# A33M11x register map
Vendor: ABOV Semiconductor Co., Ltd.; File version: 1.0
CPU: CM3 r0p1, little endian, MPU, FPU, VTOR, 4 interrupt priority bits
Registers are 32-bit, read-write, reset 0x0 unless marked. A register's access mark holds for its fields unless they carry their own. Offsets are from the block's base; [hi:lo] are bit positions; {n}, {i} and the like mark numbered series; 'fields as' and 'values as' point back to an identical list.

## MPWM0 — Motor Pulse Width Modulation
Base 0x40004000
Same registers: MPWM1 0x40005000
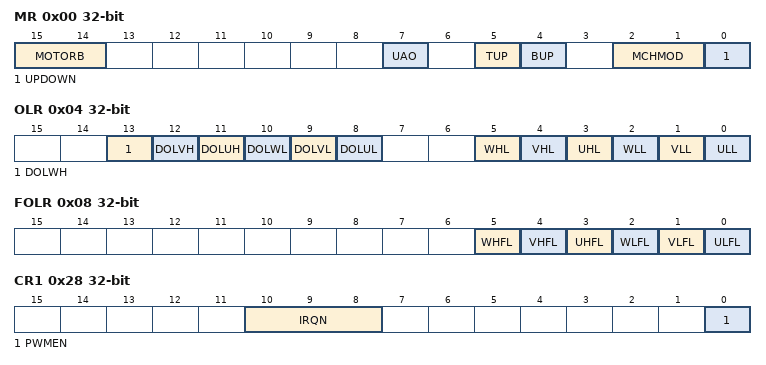
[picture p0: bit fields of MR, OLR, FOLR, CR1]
0x00 MR — MPWM n Mode Register
  [15:14] MOTORB — MPWM Mode Selection Bit
    0=MOTOR_PWM (Motor PWM Mode); 1=NORMAL_PWM (Normal PWM Mode); 3=EXTEND_PWM (Extend PWM Mode)
  [7] UAO — Update Timing Selection Bit
    0=DESIGNATE (Designate timing update); 1=ONCE (Once Duty Period Update)
  [5] TUP — DUTY, Period Update Enable bit (When same period)
    0=None Update; 1=Update
  [4] BUP — DUTY, Period Update Enable bit (When same bottom)
    0=None Update; 1=Update
  [2:1] MCHMOD — Channel Symmetry/Asymmetry Mode Selection Bit
    0=2-ch symmetry mode; 1=1-ch asymmetry mode; 2=1-ch symmetry mode
  [0] UPDOWN — PWM Up/Down Counter Mode Selection Bit
    0=UP (PWM Up Counter Mode(MOTORB = 1)); 1=UP_DOWN (Up/Down Counter Mode (MOTORB = 0, 1, 3))
0x04 OLR — MPWM n Output Level Register
  [13] DOLWH — Output level selection bit when PWMxH Disable
    0=LOW (Low Level); 1=HIGH (High Level)
  [12] DOLVH — Output level selection bit when PWMxH Disable
    0=LOW (Low Level); 1=HIGH (High Level)
  [11] DOLUH — Output level selection bit when PWMxH Disable
    0=LOW (Low Level); 1=HIGH (High Level)
  [10] DOLWL — Output level selection bit when PWMxL Disable
    0=LOW (Low Level); 1=HIGH (High Level)
  [9] DOLVL — Output level selection bit when PWMxL Disable
    0=LOW (Low Level); 1=HIGH (High Level)
  [8] DOLUL — Output level selection bit when PWMxL Disable
    0=LOW (Low Level); 1=HIGH (High Level)
  [5] WHL — Output polarity selection bit when PWMxH Start
    0=LOW (default output level(low level)); 1=HIGH (polarity output level(high level))
  [4] VHL — Output polarity selection bit when PWMxH Start
    values as WHL
  [3] UHL — Output polarity selection bit when PWMxH Start
    values as WHL
  [2] WLL — Output polarity selection bit when PWMxL Start
    values as WHL
  [1] VLL — Output polarity selection bit when PWMxL Start
    values as WHL
  [0] ULL — Output polarity selection bit when PWMxL Start
    values as WHL
0x08 FOLR — MPWM n compulsion Output Register
  [all] fields
    0=LOW (compulsion output level low); 1=HIGH (compulsion output level high)
  [5] WHFL — WH Compulsion output level selection bit
  [4] VHFL — VH Compulsion output level selection bit
  [3] UHFL — UH Compulsion output level selection bit
  [2] WLFL — WL Compulsion output level selection bit
  [1] VLFL — VL Compulsion output level selection bit
  [0] ULFL — UL Compulsion output level selection bit
0x0C PRD reset 0x2 — MPWM n Period Register
  [15:0] PERIOD — 16bit pwm period
0x10 DUH reset 0x1 — MPWM n DUTY x Register
  [15:0] DUTY_UH — 16 bit PWM Duty setting bit for X output
0x14 DVH reset 0x1 — MPWM n DUTY x Register
  [15:0] DUTY_VH — 16 bit PWM Duty setting bit for X output
0x18 DWH reset 0x1 — MPWM n DUTY x Register
  [15:0] DUTY_WH — 16 bit PWM Duty setting bit for X output
0x1C DUL reset 0x1 — MPWM n DUTY x Register
  [15:0] DUTY_UL — 16 bit PWM Duty setting bit for X output
0x20 DVL reset 0x1 — MPWM n DUTY x Register
  [15:0] DUTY_VL — 16 bit PWM Duty setting bit for X output
0x24 DWL reset 0x1 — MPWM n DUTY x Register
  [15:0] DUTY_WL — 16 bit PWM Duty setting bit for X output
0x28 CR1 — MPWM n Control Register 1
  [10:8] IRQN — IRQ number
  [0] PWMEN — PWM Enable Bit
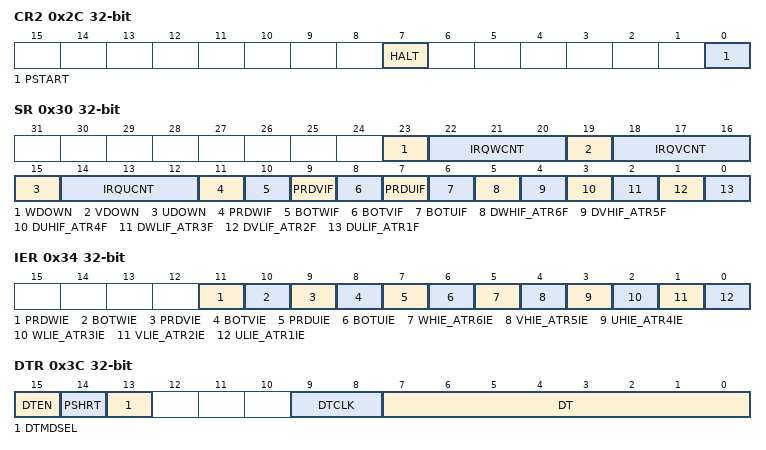
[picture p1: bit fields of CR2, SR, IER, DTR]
0x2C CR2 — MPWM n Control Register 2
  [7] HALT — PWM HALT
  [0] PSTART — PWM Phase x counter start
0x30 SR — MPWM n Status Register
  [23] WDOWN ro — Current PWM Counter Mode
  [22:20] IRQWCNT ro — Interrupt Counter Number of Period Match
  [19] VDOWN ro — Current PWM Counter Mode
  [18:16] IRQVCNT ro — Interrupt Counter Number of Period Match
  [15] UDOWN ro — Current PWM Counter Mode
  [14:12] IRQUCNT ro — Interrupt Counter Number of Period Match
  [11] PRDWIF — PWM Period Interrupt Flag
  [10] BOTWIF — PWM Bottom Interrupt Flag
  [9] PRDVIF — PWM Period Interrupt Flag
  [8] BOTVIF — PWM Bottom Interrupt Flag
  [7] PRDUIF — PWM Period Interrupt Flag
  [6] BOTUIF — PWM Bottom Interrupt Flag
  [5] DWHIF_ATR6F — PWM Duty Interrupt Flag (Duty Interrupt Enable when ATR6 disable)
  [4] DVHIF_ATR5F — PWM Duty Interrupt Flag (Duty Interrupt Enable when ATR6 disable)
  [3] DUHIF_ATR4F — PWM Duty Interrupt Flag (Duty Interrupt Enable when ATR6 disable)
  [2] DWLIF_ATR3F — PWM Duty Interrupt Flag (Duty Interrupt Enable when ATR6 disable)
  [1] DVLIF_ATR2F — PWM Duty Interrupt Flag (Duty Interrupt Enable when ATR6 disable)
  [0] DULIF_ATR1F — PWM Duty Interrupt Flag (Duty Interrupt Enable when ATR6 disable)
0x34 IER — MPWM n Interrupt Enable Register
  [11] PRDWIE — PWM Counter Period Interrupt Enable bit
  [10] BOTWIE — PWM Counter Botom Interrupt Enable bit
  [9] PRDVIE — PWM Counter Period Interrupt Enable bit
  [8] BOTVIE — PWM Counter Botom Interrupt Enable bit
  [7] PRDUIE — PWM Counter Period Interrupt Enable bit
  [6] BOTUIE — PWM Counter Botom Interrupt Enable bit
  [5] WHIE_ATR6IE — Duty or ATR6 Match Interrupt Enable bit
  [4] VHIE_ATR5IE — Duty or ATR5 Match Interrupt Enable bit
  [3] UHIE_ATR4IE — Duty or ATR4 Match Interrupt Enable bit
  [2] WLIE_ATR3IE — Duty or ATR3 Match Interrupt Enable bit
  [1] VLIE_ATR2IE — Duty or ATR2 Match Interrupt Enable bit
  [0] ULIE_ATR1IE — Duty or ATR1 Match Interrupt Enable bit
0x38 CNT — MPWM n Counter Register
  [15:0] CNT — PWM Counter Value
0x3C DTR — MPWM n Dead-Time Register
  [15] DTEN — Dead-time Function Enable Bit
  [14] PSHRT — Short Protecion Bit
  [13] DTMDSEL — Dead-time Operation Mode Selection Bit
    0=Before_H_After_L (Insert Before of PWMxH, After of PWMxL); 1=Before_L_After_H (Insert Before of PWMxL, After of PWMxH)
  [9:8] DTCLK — Dead-time Prescaler Setting Bit
    0=PWMCLK_BY_2 (Dead-time counter is PWM CLK/2); 1=PWMCLK_BY_4 (Dead-time counter is PWM CLK/4); 2=PWMCLK_BY_8 (Dead-time counter is PWM CLK/8); 3=PWMCLK_BY_16 (Dead-time counter is PWM CLK/16)
  [7:0] DT — Rising/Falling Edge Dead-time Value
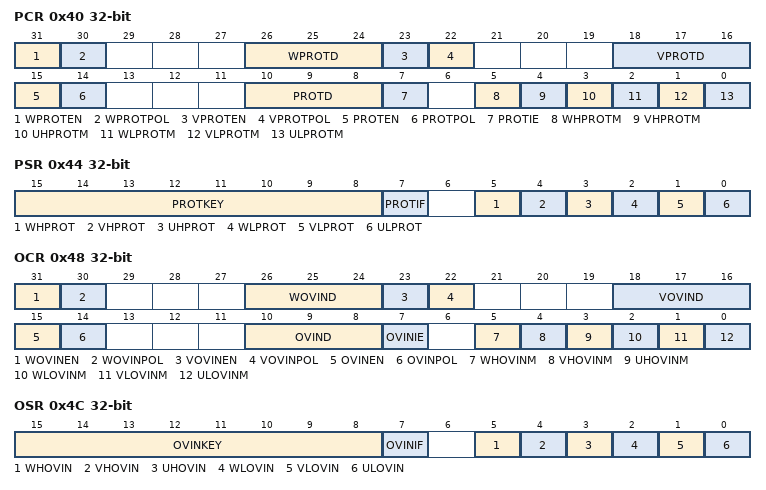
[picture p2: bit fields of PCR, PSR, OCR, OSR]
0x40 PCR — MPWM n Protection Control Register
  [31] WPROTEN — Protection Input Enable
  [30] WPROTPOL — Protection Input Polarity Selection Bit
  [26:24] WPROTD — Protection Input Debounce
  [23] VPROTEN — Protection Input Enable
  [22] VPROTPOL — Protection Input Polarity Selection Bit
  [18:16] VPROTD — Protection Input Debounce
  [15] PROTEN — Protection Input Enable
  [14] PROTPOL — Protection Input Polarity Selection
  [10:8] PROTD — Protection Input Debounce
  [7] PROTIE — Protection Interrupt Enable
  [5] WHPROTM — Ph-W, H Protection Output Enable
  [4] VHPROTM — Ph-V, H Protection Output Enable
  [3] UHPROTM — Ph-U, H Protection Output Enable
  [2] WLPROTM — Ph-W, L Protection Output Enable
  [1] VLPROTM — Ph-V, L Protection Output Enable
  [0] ULPROTM — Ph-U, L Protection Output Enable
0x44 PSR — MPWM n Protection Status Register
  [15:8] PROTKEY wo — Protection Clear Access Key (KEY : 0xCA)
  [7] PROTIF — Protection Interrupt Status
  [5] WHPROT — Ph-W, H Protection Flag
  [4] VHPROT — Ph-V, H Protection Flag
  [3] UHPROT — Ph-U, H Protection Flag
  [2] WLPROT — Ph-W, L Protection Flag
  [1] VLPROT — Ph-V, L Protection Flag
  [0] ULPROT — Ph-U, L Protection Flag
0x48 OCR — MPWM n Overvoltage Control Register
  [31] WOVINEN — Overvoltage Input Enable
  [30] WOVINPOL — Overvoltage Input Polarity Selection Bit
  [26:24] WOVIND — Overvoltage Input Debounce
  [23] VOVINEN — Overvoltage Input Enable
  [22] VOVINPOL — Overvoltage Input Polarity Selection Bit
  [18:16] VOVIND — Overvoltage Input Debounce
  [15] OVINEN — Overvoltage Input Enable
  [14] OVINPOL — Overvoltage Input Polarity Selection
  [10:8] OVIND — Overvoltage Input Debounce
  [7] OVINIE — Overvoltage Interrupt Enable
  [5] WHOVINM — Ph-W, H Protection Output Enable
  [4] VHOVINM — Ph-V, H Protection Output Enable
  [3] UHOVINM — Ph-U, H Protection Output Enable
  [2] WLOVINM — Ph-W, L Protection Output Enable
  [1] VLOVINM — Ph-V, L Protection Output Enable
  [0] ULOVINM — Ph-U, L Protection Output Enable
0x4C OSR — MPWM n Overvoltage Status Register
  [15:8] OVINKEY wo — Overvoltage Clear Access Key (KEY : 0xAC)
  [7] OVINIF — Overvoltage Interrupt Status
  [5] WHOVIN — Ph-W, H Protection Flag
  [4] VHOVIN — Ph-V, H Protection Flag
  [3] UHOVIN — Ph-U, H Protection Flag
  [2] WLOVIN — Ph-W, L Protection Flag
  [1] VLOVIN — Ph-V, L Protection Flag
  [0] ULOVIN — Ph-U, L Protection Flag
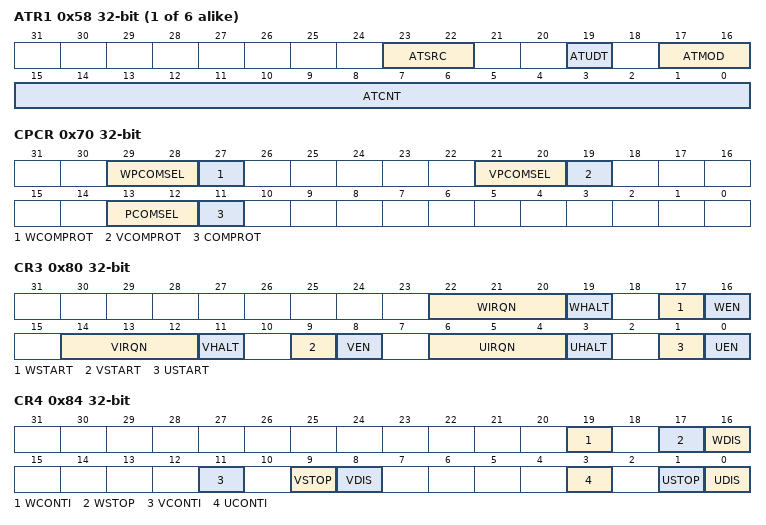
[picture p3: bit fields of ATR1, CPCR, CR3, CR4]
{0x54+4i} ATR{i} (i=1..6) — MPWM n ADC Trigger Counter m Register
  [23:22] ATSRC — ADC Trigger Source Counter
    0=Ph-U Counter Compare source; 1=Ph-V Counter Compare source; 2=Ph-W Counter Compare source
  [19] ATUDT — ADC Register Update Mode
  [17:16] ATMOD — ADC Trigger Mode Selection Register
    0=Disable (ADC Trigger Disable); 1=UP_Count (Trigger out When up counter match); 2=DOWN_Count (Trigger out When down counter match); 3=UP-DOWN_Count (Trigger out When up-down counter match)
  [15:0] ATCNT — ADC Trigger Counter (only less then PWM Period)
0x70 CPCR — MPWM n Comparator protection control Register
  [29:28] WPCOMSEL — Protection comparator peripheral selection (Phase W)
  [27] WCOMPROT — Whether to enable or disable comparator protection input (Phase W)
  [21:20] VPCOMSEL — Protection comparator peripheral selection (Phase V)
  [19] VCOMPROT — Whether to enable or disable comparator protection input (Phase V)
  [13:12] PCOMSEL — Protection comparator peripheral selection (Phase U)
  [11] COMPROT — Whether to enable or disable comparator protection input (Phase U)
0x80 CR3 — MPWM n Control Register 3
  [22:20] WIRQN — Ph-W Interrupt Interval Setting
  [19] WHALT — Ph-W counter stop in current status
  [17] WSTART — Ph-W Start Bit
  [16] WEN — Ph-W Enable Bit
  [14:12] VIRQN — Ph-V Interrupt Interval Setting
  [11] VHALT — Ph-V counter stop in current status
  [9] VSTART — Ph-V Start Bit
  [8] VEN — Ph-V Enable Bit
  [6:4] UIRQN — Ph-U Interrupt Interval Setting
  [3] UHALT — Ph-U counter stop in current status
  [1] USTART — Ph-U Start Bit
  [0] UEN — Ph-V Enable Bit
0x84 CR4 — MPWM n Control Register 4
  [19] WCONTI — Ph-W Counter Continuous Setting
  [17] WSTOP — Ph-W Counter Stop and Reset Setting
  [16] WDIS — Ph-W Disable Setting (Status reset)
  [11] VCONTI — Ph-V Counter Continuous Setting
  [9] VSTOP — Ph-V Counter Stop and Reset Setting
  [8] VDIS — Ph-W Disable Setting (Status reset)
  [3] UCONTI — Ph-U Counter Continuous Setting
  [1] USTOP — Ph-U Counter Stop and Reset Setting
  [0] UDIS — Ph-U Disable Setting (Status reset)
0x90 PRDU reset 0x2 — MPWM n Phase U Period Register
  [15:0] PERIOD_U — 16bit pwm period
0x94 PRDV reset 0x2 — MPWM n Phase V Period Register
  [15:0] PERIOD_V — 16bit pwm period
0x98 PRDW reset 0x2 — MPWM n Phase W Period Register
  [15:0] PERIOD_W — 16bit pwm period
0xA0 CNTU — MPWM n Counter U Register
  [15:0] CNT_U — PWM Counter Value
0xA4 CNTV — MPWM n Counter V Register
  [15:0] CNT_V — PWM Counter Value
0xA8 CNTW — MPWM n Counter W Register
  [15:0] CNT_W — PWM Counter Value
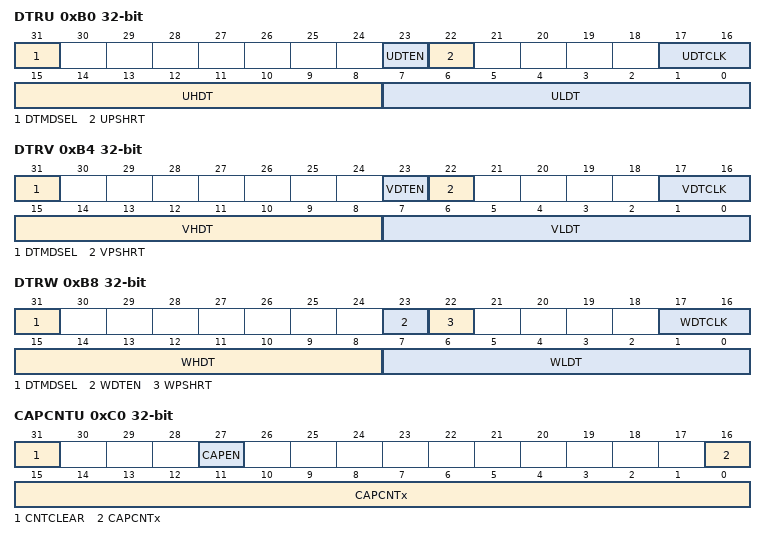
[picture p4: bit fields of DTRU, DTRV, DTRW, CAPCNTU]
0xB0 DTRU — MPWM n Dead-Time Register
  [31] DTMDSEL — Dead-time Operation Mode Selection Bit
    0=Before_H_After_L (dead-time insert before PWMxH, After PWMxL); 1=Before_L_After_H (dead-time insert before PWMxL, After PWMxH)
  [23] UDTEN — Dead-time Function Enable Bit
  [22] UPSHRT — Short Condition Protection
  [17:16] UDTCLK — Dead-time Prescaler
    values as DTR.DTCLK
  [15:8] UHDT — Rising Dead-time Value Bit
  [7:0] ULDT — Falling Dead-time Value Bit
0xB4 DTRV — MPWM n Dead-Time Register
  [31] DTMDSEL — Dead-time Operation Mode Selection Bit
    values as DTRU.DTMDSEL
  [23] VDTEN — Dead-time Function Enable Bit
  [22] VPSHRT — Short Condition Protection
  [17:16] VDTCLK — Dead-time Prescaler
    values as DTR.DTCLK
  [15:8] VHDT — Rising Dead-time Value Bit
  [7:0] VLDT — Falling Dead-time Value Bit
0xB8 DTRW — MPWM n Dead-Time Register
  [31] DTMDSEL — Dead-time Operation Mode Selection Bit
    values as DTRU.DTMDSEL
  [23] WDTEN — Dead-time Function Enable Bit
  [22] WPSHRT — Short Condition Protection
  [17:16] WDTCLK — Dead-time Prescaler
    values as DTR.DTCLK
  [15:8] WHDT — Rising Dead-time Value Bit
  [7:0] WLDT — Falling Dead-time Value Bit
0xC0 CAPCNTU — MPWM n Capture Counter Register (Ph-U)
  [31] CNTCLEAR wo — Capture Counter Clear Bit
  [27] CAPEN — Capture Function Enable bit
  [16:0] CAPCNTx ro — Capture Counter Value Bit
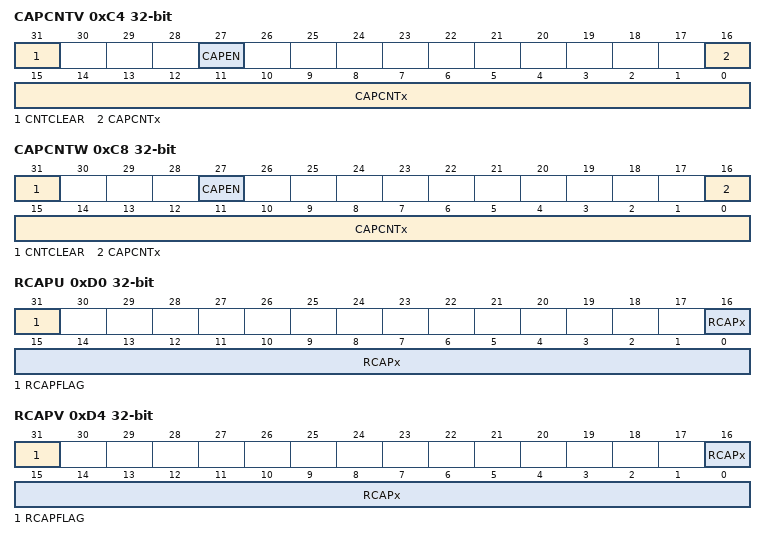
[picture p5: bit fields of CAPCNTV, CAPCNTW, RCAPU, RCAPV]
0xC4 CAPCNTV — MPWM n Capture Counter Register (Ph-V)
  fields as CAPCNTU
0xC8 CAPCNTW — MPWM n Capture Counter Register (Ph-W)
  fields as CAPCNTU
0xD0 RCAPU — MPWM n Capture Rising Value Register (Ph-U)
  [31] RCAPFLAG — Capture Counter Flag (Clear RCAPx and Flag, write '1')
  [16:0] RCAPx ro — Rising Capture Counter Value Bit
0xD4 RCAPV — MPWM n Capture Rising Value Register (Ph-V)
  fields as RCAPU
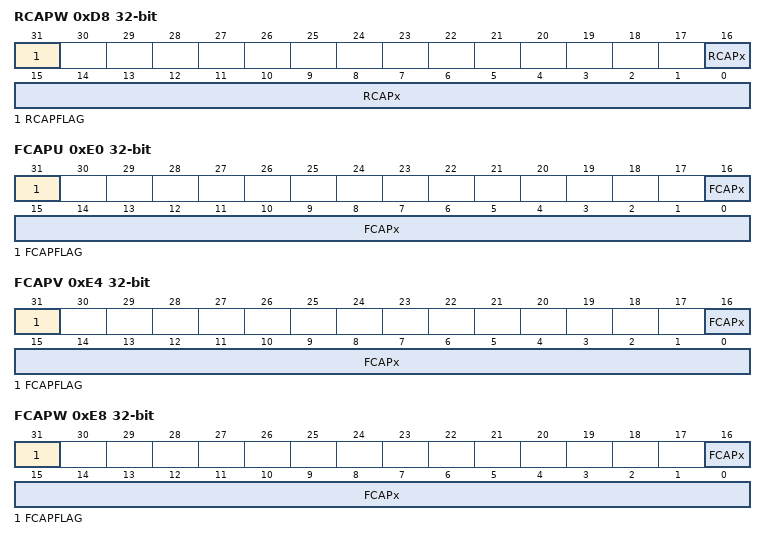
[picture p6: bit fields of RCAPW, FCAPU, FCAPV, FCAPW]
0xD8 RCAPW — MPWM n Capture Rising Value Register (Ph-W)
  fields as RCAPU
0xE0 FCAPU — MPWM n Capture Falling Value Register (Ph-U)
  [31] FCAPFLAG — Capture Counter Flag (Clear FCAPx and Flag, write '1')
  [16:0] FCAPx ro — Falling Capture Counter Value Bit
0xE4 FCAPV — MPWM n Capture Falling Value Register (Ph-V)
  fields as FCAPU
0xE8 FCAPW — MPWM n Capture Falling Value Register (Ph-W)
  fields as FCAPU
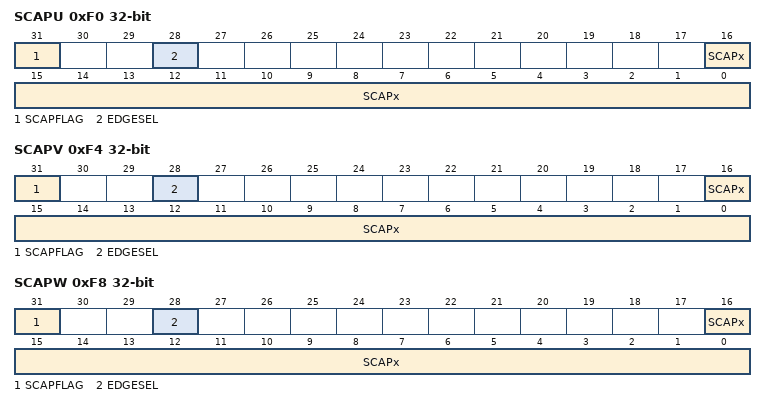
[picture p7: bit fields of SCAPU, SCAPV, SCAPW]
0xF0 SCAPU — MPWM n Sub Capture Value Register (Ph-U)
  [31] SCAPFLAG — Sub Capture Counter Flag (Clear SCAPx and Flag, write '1')
  [28] EDGESEL — External Signal Capture Edge Selection Bit
  [16:0] SCAPx ro — Sub Capture Counter Value Bit
0xF4 SCAPV — MPWM n Sub Capture Value Register (Ph-V)
  fields as SCAPU
0xF8 SCAPW — MPWM n Sub Capture Value Register (Ph-W)
  fields as SCAPU
